# HDSC_HC32F460KCTA register map
Vendor: HDSC; Series: ARMCM4; File version: 1.0
CPU: CM4 r0p1, little endian, MPU, FPU, 4 interrupt priority bits
Registers are 32-bit, read-write, reset 0x0 unless marked. A register's access mark holds for its fields unless they carry their own. Offsets are from the block's base; [hi:lo] are bit positions; {n}, {i} and the like mark numbered series.

## CMPCR
Base 0x4004A000; alternate view of CMP1
0x100 DADR1 16-bit
  [7:0] DATA
0x102 DADR2 16-bit
  [7:0] DATA
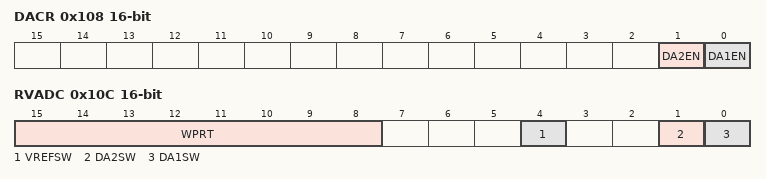
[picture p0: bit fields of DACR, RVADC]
0x108 DACR 16-bit
  [1] DA2EN, [0] DA1EN
0x10C RVADC 16-bit (reset mask 0x13)
  [15:8] WPRT, [4] VREFSW, [1] DA2SW, [0] DA1SW

## CMU
Base 0x40054000
0x10 PERICKSEL 16-bit
  [3:0] PERICKSEL
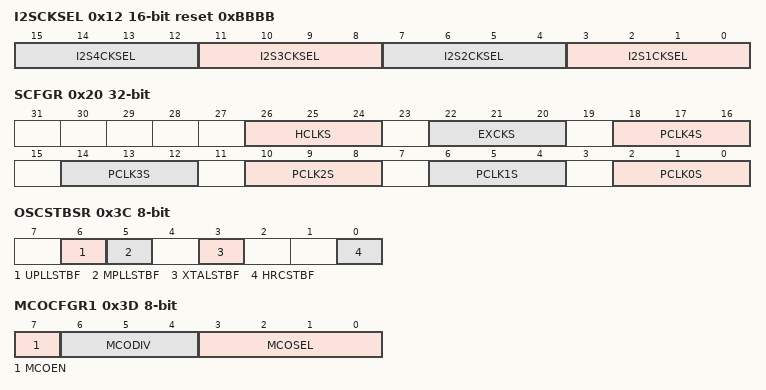
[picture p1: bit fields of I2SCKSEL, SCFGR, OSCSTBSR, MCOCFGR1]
0x12 I2SCKSEL 16-bit reset 0xBBBB
  [4n-1:4n-4] I2S{n}CKSEL (n=1..4)
0x20 SCFGR
  [26:24] HCLKS, [22:20] EXCKS, [4n+2:4n] PCLK{n}S (n=0..4)
0x24 USBCKCFGR 8-bit reset 0x40
  [7:4] USBCKS
0x26 CKSWR 8-bit reset 0x1
  [2:0] CKSW
0x2A PLLCR 8-bit reset 0x1
  [0] MPLLOFF
0x2E UPLLCR 8-bit reset 0x1
  [0] UPLLOFF
0x32 XTALCR 8-bit reset 0x1
  [0] XTALSTP
0x36 HRCCR 8-bit reset 0x1
  [0] HRCSTP
0x38 MRCCR 8-bit reset 0x80
  [0] MRCSTP
0x3C OSCSTBSR 8-bit
  [6] UPLLSTBF, [5] MPLLSTBF, [3] XTALSTBF, [0] HRCSTBF
0x3D MCOCFGR1 8-bit
  [7] MCOEN, [6:4] MCODIV, [3:0] MCOSEL
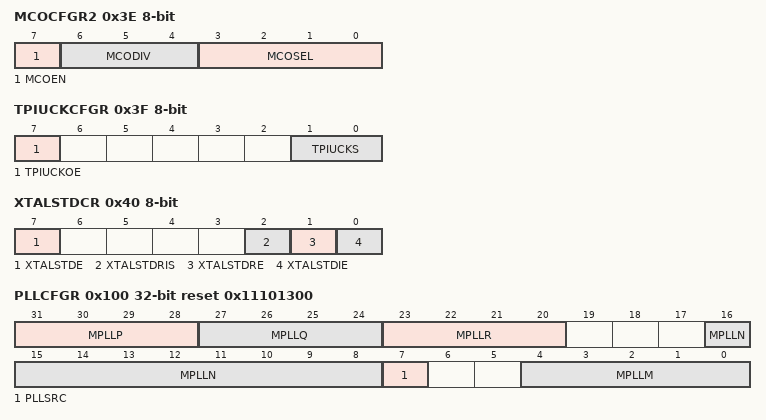
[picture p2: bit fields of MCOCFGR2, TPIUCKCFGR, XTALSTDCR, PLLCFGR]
0x3E MCOCFGR2 8-bit
  [7] MCOEN, [6:4] MCODIV, [3:0] MCOSEL
0x3F TPIUCKCFGR 8-bit
  [7] TPIUCKOE, [1:0] TPIUCKS
0x40 XTALSTDCR 8-bit
  [7] XTALSTDE, [2] XTALSTDRIS, [1] XTALSTDRE, [0] XTALSTDIE
0x41 XTALSTDSR 8-bit
  [0] XTALSTDF
0x61 MRCTRM 8-bit
0x62 HRCTRM 8-bit
0xA2 XTALSTBCR 8-bit reset 0x5
  [3:0] XTALSTB
0x100 PLLCFGR reset 0x11101300
  [31:28] MPLLP, [27:24] MPLLQ, [23:20] MPLLR, [16:8] MPLLN, [7] PLLSRC, [4:0] MPLLM
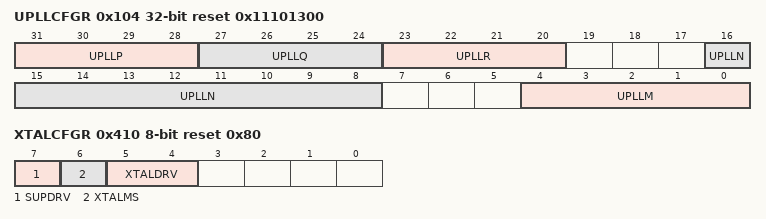
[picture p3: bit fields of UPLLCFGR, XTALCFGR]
0x104 UPLLCFGR reset 0x11101300
  [31:28] UPLLP, [27:24] UPLLQ, [23:20] UPLLR, [16:8] UPLLN, [4:0] UPLLM
0x410 XTALCFGR 8-bit reset 0x80
  [7] SUPDRV, [6] XTALMS, [5:4] XTALDRV
0x420 XTAL32CR 8-bit
  [0] XTAL32STP
0x421 XTAL32CFGR 8-bit
  [2:0] XTAL32DRV
0x425 XTAL32NFR 8-bit
  [1:0] XTAL32NF
0x427 LRCCR 8-bit
  [0] LRCSTP
0x429 LRCTRM 8-bit

## CRC
Base 0x40008C00
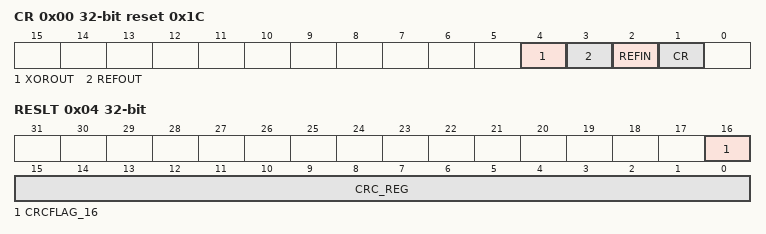
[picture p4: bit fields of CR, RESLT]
0x00 CR reset 0x1C
  [4] XOROUT, [3] REFOUT, [2] REFIN, [1] CR
0x04 RESLT
  [16] CRCFLAG_16 ro, [15:0] CRC_REG
0x0C FLG ro reset 0x1
  [0] CRCFLAG_32
{0x80+4i} DAT{i} ro (i=0..31)

## DBGC
Base 0xE0042000
{0x0+4i} AUTHID{i} (i=0..2)
0x0C RESV0
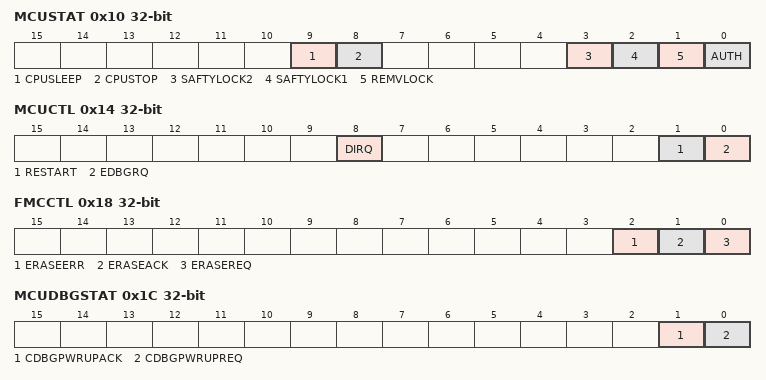
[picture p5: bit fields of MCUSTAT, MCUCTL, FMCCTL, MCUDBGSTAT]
0x10 MCUSTAT
  [9] CPUSLEEP, [8] CPUSTOP, [3] SAFTYLOCK2, [2] SAFTYLOCK1, [1] REMVLOCK, [0] AUTH
0x14 MCUCTL
  [8] DIRQ, [1] RESTART, [0] EDBGRQ
0x18 FMCCTL
  [2] ERASEERR, [1] ERASEACK, [0] ERASEREQ
0x1C MCUDBGSTAT
  [1] CDBGPWRUPACK, [0] CDBGPWRUPREQ
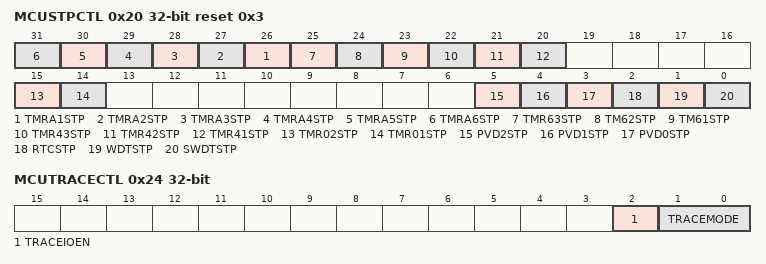
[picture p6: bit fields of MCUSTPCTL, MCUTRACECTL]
0x20 MCUSTPCTL reset 0x3
  [n+25] TMRA{n}STP (n=1..6), [25] TMR63STP, [24] TM62STP, [23] TM61STP, [22] TMR43STP, [21] TMR42STP, [20] TMR41STP, [15] TMR02STP, [14] TMR01STP, [5] PVD2STP, [4] PVD1STP, [3] PVD0STP, [2] RTCSTP, [1] WDTSTP, [0] SWDTSTP
0x24 MCUTRACECTL
  [2] TRACEIOEN, [1:0] TRACEMODE

## DCU1 — desc DCU
Base 0x40052000
Same registers: DCU2 0x40052400, DCU3 0x40052800, DCU4 0x40052C00
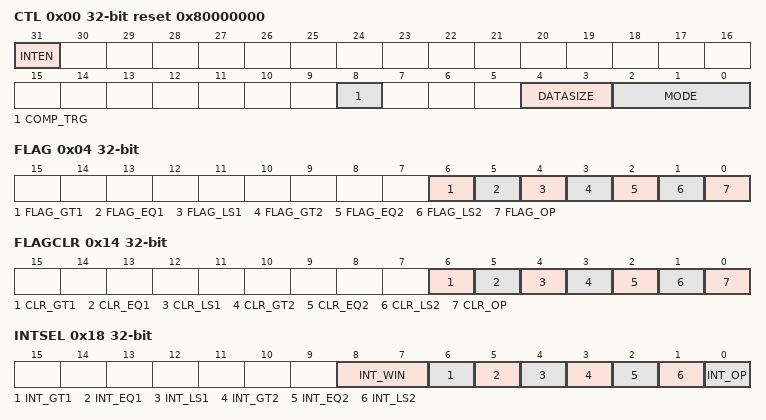
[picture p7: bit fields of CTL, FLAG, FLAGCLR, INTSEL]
0x00 CTL reset 0x80000000
  [31] INTEN, [8] COMP_TRG, [4:3] DATASIZE, [2:0] MODE
0x04 FLAG ro
  [6] FLAG_GT1, [5] FLAG_EQ1, [4] FLAG_LS1, [3] FLAG_GT2, [2] FLAG_EQ2, [1] FLAG_LS2, [0] FLAG_OP
{0x8+4i} DATA{i} (i=0..2)
0x14 FLAGCLR wo
  [6] CLR_GT1, [5] CLR_EQ1, [4] CLR_LS1, [3] CLR_GT2, [2] CLR_EQ2, [1] CLR_LS2, [0] CLR_OP
0x18 INTSEL
  [8:7] INT_WIN, [6] INT_GT1, [5] INT_EQ1, [4] INT_LS1, [3] INT_GT2, [2] INT_EQ2, [1] INT_LS2, [0] INT_OP

## DMA1 — desc DMA
Base 0x40053000
Same registers: DMA2 0x40053400
0x00 EN
  [0] EN
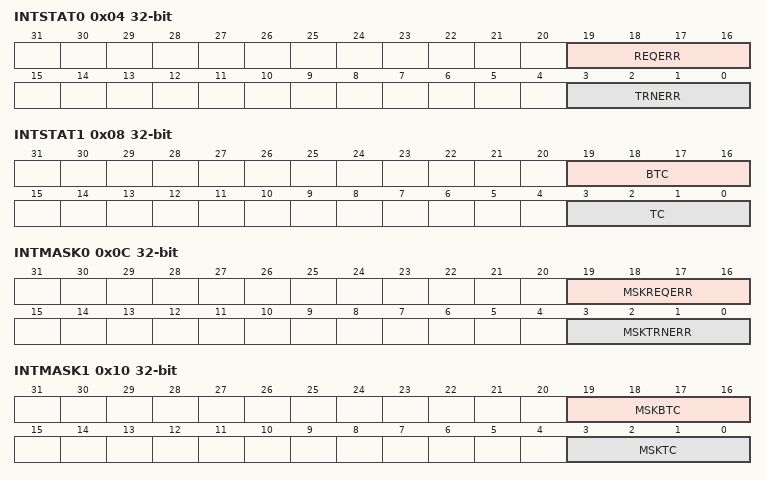
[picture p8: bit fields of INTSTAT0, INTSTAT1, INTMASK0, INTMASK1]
0x04 INTSTAT0 ro
  [19:16] REQERR, [3:0] TRNERR
0x08 INTSTAT1 ro
  [19:16] BTC, [3:0] TC
0x0C INTMASK0
  [19:16] MSKREQERR, [3:0] MSKTRNERR
0x10 INTMASK1
  [19:16] MSKBTC, [3:0] MSKTC
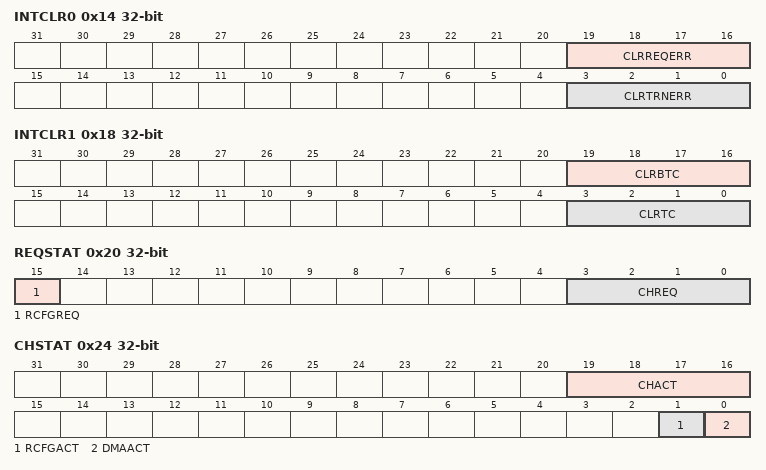
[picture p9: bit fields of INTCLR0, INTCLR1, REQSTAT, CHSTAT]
0x14 INTCLR0 wo
  [19:16] CLRREQERR, [3:0] CLRTRNERR
0x18 INTCLR1 wo
  [19:16] CLRBTC, [3:0] CLRTC
0x1C CHEN
  [3:0] CHEN
0x20 REQSTAT ro
  [15] RCFGREQ, [3:0] CHREQ
0x24 CHSTAT ro
  [19:16] CHACT, [1] RCFGACT, [0] DMAACT
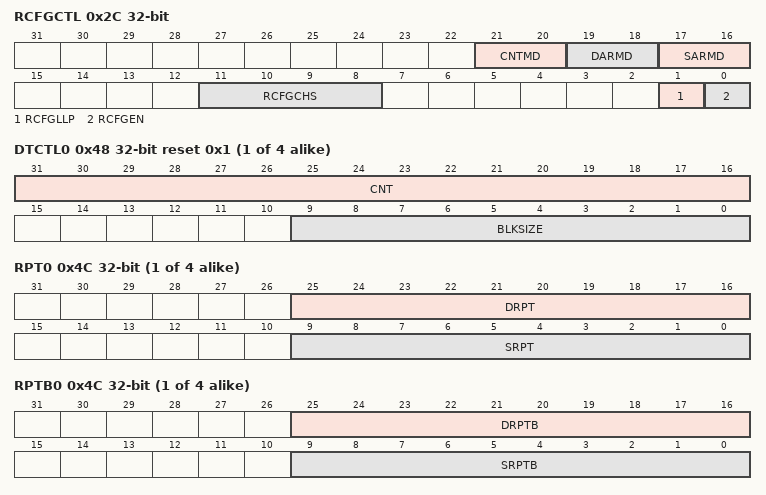
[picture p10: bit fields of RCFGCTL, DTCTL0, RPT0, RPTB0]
0x2C RCFGCTL
  [21:20] CNTMD, [19:18] DARMD, [17:16] SARMD, [11:8] RCFGCHS, [1] RCFGLLP, [0] RCFGEN
{0x40+0x40*i} SAR{i} (i=0..3)
{0x44+0x40*i} DAR{i} (i=0..3)
{0x48+0x40*i} DTCTL{i} reset 0x1 (i=0..3)
  [31:16] CNT, [9:0] BLKSIZE
{0x4C+0x40*i} RPT{i} (i=0..3)
  [25:16] DRPT, [9:0] SRPT
{0x4C+0x40*i} RPTB{i} (i=0..3)
  [25:16] DRPTB, [9:0] SRPTB
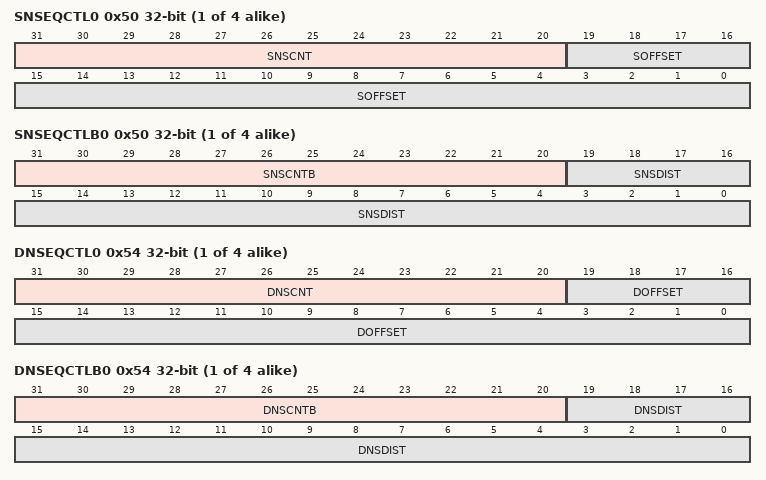
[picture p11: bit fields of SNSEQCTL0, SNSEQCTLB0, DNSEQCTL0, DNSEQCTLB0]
{0x50+0x40*i} SNSEQCTL{i} (i=0..3)
  [31:20] SNSCNT, [19:0] SOFFSET
{0x50+0x40*i} SNSEQCTLB{i} (i=0..3)
  [31:20] SNSCNTB, [19:0] SNSDIST
{0x54+0x40*i} DNSEQCTL{i} (i=0..3)
  [31:20] DNSCNT, [19:0] DOFFSET
{0x54+0x40*i} DNSEQCTLB{i} (i=0..3)
  [31:20] DNSCNTB, [19:0] DNSDIST
{0x58+0x40*i} LLP{i} (i=0..3)
  [31:2] LLP
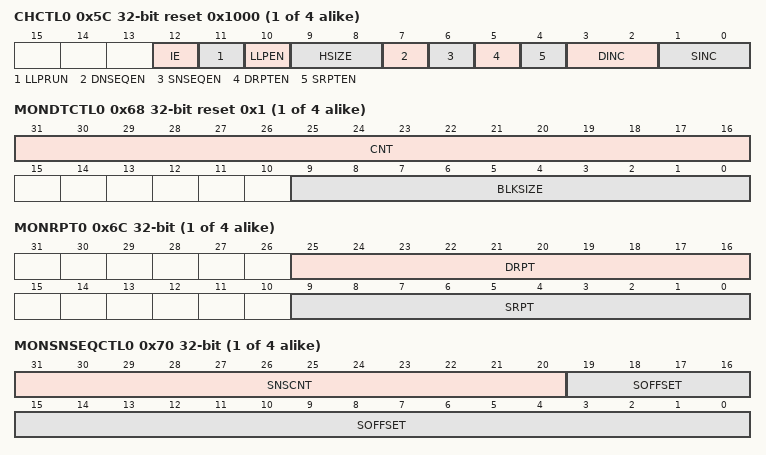
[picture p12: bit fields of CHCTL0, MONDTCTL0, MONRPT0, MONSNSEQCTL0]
{0x5C+0x40*i} CHCTL{i} reset 0x1000 (i=0..3)
  [12] IE, [11] LLPRUN, [10] LLPEN, [9:8] HSIZE, [7] DNSEQEN, [6] SNSEQEN, [5] DRPTEN, [4] SRPTEN, [3:2] DINC, [1:0] SINC
{0x60+0x40*i} MONSAR{i} ro (i=0..3)
{0x64+0x40*i} MONDAR{i} ro (i=0..3)
{0x68+0x40*i} MONDTCTL{i} ro reset 0x1 (i=0..3)
  [31:16] CNT, [9:0] BLKSIZE
{0x6C+0x40*i} MONRPT{i} ro (i=0..3)
  [25:16] DRPT, [9:0] SRPT
{0x70+0x40*i} MONSNSEQCTL{i} ro (i=0..3)
  [31:20] SNSCNT, [19:0] SOFFSET
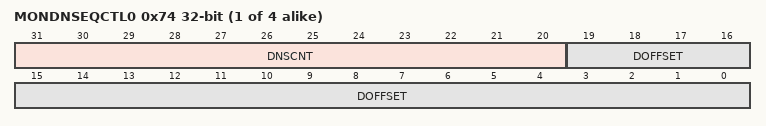
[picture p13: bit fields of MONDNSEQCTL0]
{0x74+0x40*i} MONDNSEQCTL{i} ro (i=0..3)
  [31:20] DNSCNT, [19:0] DOFFSET
